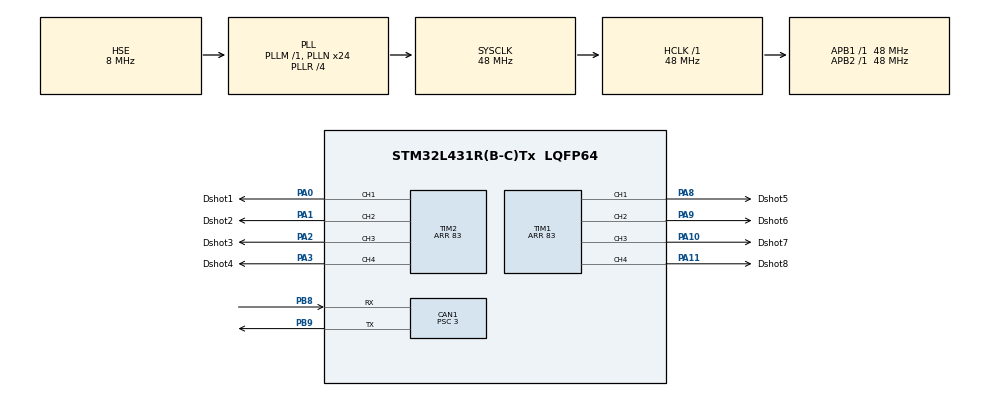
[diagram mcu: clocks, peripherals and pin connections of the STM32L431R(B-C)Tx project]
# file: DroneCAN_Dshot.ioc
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CAN1.ABOM=ENABLE
CAN1.BS1=CAN_BS1_13TQ
CAN1.BS2=CAN_BS2_2TQ
CAN1.CalculateBaudRate=1000000
CAN1.CalculateTimeBit=1000
CAN1.CalculateTimeQuantum=62.5
CAN1.NART=ENABLE
CAN1.Prescaler=3
CAN1.SJW=CAN_SJW_1TQ
Dma.Request0=TIM1_UP
Dma.Request1=TIM2_UP
Dma.TIM1_UP.0.Direction=DMA_MEMORY_TO_PERIPH
Dma.TIM1_UP.0.Instance=DMA1_Channel6
Dma.TIM1_UP.0.MemDataAlignment=DMA_MDATAALIGN_WORD
Dma.TIM1_UP.0.MemInc=DMA_MINC_ENABLE
Dma.TIM1_UP.0.Mode=DMA_NORMAL
Dma.TIM1_UP.0.PeriphDataAlignment=DMA_PDATAALIGN_WORD
Dma.TIM1_UP.0.PeriphInc=DMA_PINC_DISABLE
Dma.TIM1_UP.0.Priority=DMA_PRIORITY_VERY_HIGH
Dma.TIM2_UP.1.Direction=DMA_MEMORY_TO_PERIPH
Dma.TIM2_UP.1.Instance=DMA1_Channel2
Dma.TIM2_UP.1.MemDataAlignment=DMA_MDATAALIGN_WORD
Dma.TIM2_UP.1.MemInc=DMA_MINC_ENABLE
Dma.TIM2_UP.1.Mode=DMA_NORMAL
Dma.TIM2_UP.1.PeriphDataAlignment=DMA_PDATAALIGN_WORD
Dma.TIM2_UP.1.PeriphInc=DMA_PINC_DISABLE
Dma.TIM2_UP.1.Priority=DMA_PRIORITY_VERY_HIGH
IWDG.Prescaler=IWDG_PRESCALER_32
IWDG.Reload=399
Mcu.Family=STM32L4
Mcu.Name=STM32L431R(B-C)Tx
Mcu.Package=LQFP64
NVIC.CAN1_RX0_IRQn=true\:2\:0\:false\:false\:true\:true\:true\:true
NVIC.DMA1_Channel2_IRQn=true\:0\:0\:false\:false\:true\:false\:true\:true
NVIC.DMA1_Channel6_IRQn=true\:0\:0\:false\:false\:true\:false\:true\:true
NVIC.PriorityGroup=NVIC_PRIORITYGROUP_4
NVIC.TIM6_DAC_IRQn=true\:0\:0\:false\:false\:true\:true\:true\:true
NVIC.TIM7_IRQn=true\:0\:0\:false\:false\:true\:true\:true\:true
PA0.GPIO_Label=Dshot1
PA0.GPIO_Speed=GPIO_SPEED_FREQ_VERY_HIGH
PA0.Signal=S_TIM2_CH1
PA1.GPIO_Label=Dshot2
PA1.GPIO_Speed=GPIO_SPEED_FREQ_VERY_HIGH
PA1.Signal=S_TIM2_CH2
PA10.GPIO_Label=Dshot7
PA10.GPIO_Speed=GPIO_SPEED_FREQ_VERY_HIGH
PA10.Signal=S_TIM1_CH3
PA11.GPIO_Label=Dshot8
PA11.GPIO_Speed=GPIO_SPEED_FREQ_VERY_HIGH
PA11.Signal=S_TIM1_CH4
PA13\ (JTMS-SWDIO).Mode=Serial_Wire
PA13\ (JTMS-SWDIO).Signal=SYS_JTMS-SWDIO
PA14\ (JTCK-SWCLK).Mode=Serial_Wire
PA14\ (JTCK-SWCLK).Signal=SYS_JTCK-SWCLK
PA2.GPIO_Label=Dshot3
PA2.GPIO_Speed=GPIO_SPEED_FREQ_VERY_HIGH
PA2.Signal=S_TIM2_CH3
PA3.GPIO_Label=Dshot4
PA3.GPIO_Speed=GPIO_SPEED_FREQ_VERY_HIGH
PA3.Signal=S_TIM2_CH4
PA8.GPIO_Label=Dshot5
PA8.GPIO_Speed=GPIO_SPEED_FREQ_VERY_HIGH
PA8.Signal=S_TIM1_CH1
PA9.GPIO_Label=Dshot6
PA9.GPIO_Speed=GPIO_SPEED_FREQ_VERY_HIGH
PA9.Signal=S_TIM1_CH2
PB8.Mode=CAN_Activate
PB8.Signal=CAN1_RX
PB9.Mode=CAN_Activate
PB9.Signal=CAN1_TX
PH0-OSC_IN\ (PH0).Mode=HSE-External-Oscillator
PH0-OSC_IN\ (PH0).Signal=RCC_OSC_IN
PH1-OSC_OUT\ (PH1).Mode=HSE-External-Oscillator
PH1-OSC_OUT\ (PH1).Signal=RCC_OSC_OUT
ProjectManager.HeapSize=0x200
ProjectManager.StackSize=0x400
ProjectManager.TargetToolchain=CMake
RCC.ADCFreq_Value=32000000
RCC.AHBFreq_Value=48000000
RCC.APB1Freq_Value=48000000
RCC.APB1TimFreq_Value=48000000
RCC.APB2Freq_Value=48000000
RCC.APB2TimFreq_Value=48000000
RCC.CortexFreq_Value=48000000
RCC.HCLKFreq_Value=48000000
RCC.HSE_VALUE=8000000
RCC.HSI48_VALUE=48000000
RCC.HSI_VALUE=16000000
RCC.LSE_VALUE=32768
RCC.MSI_VALUE=4000000
RCC.PLLN=24
RCC.PLLR=RCC_PLLR_DIV4
RCC.PLLSourceVirtual=RCC_PLLSOURCE_HSE
RCC.SYSCLKFreq_VALUE=48000000
RCC.SYSCLKSource=RCC_SYSCLKSOURCE_PLLCLK
RCC.VCOOutputFreq_Value=192000000
SH.S_TIM1_CH1.0=TIM1_CH1,PWM Generation1 CH1
SH.S_TIM1_CH2.0=TIM1_CH2,PWM Generation2 CH2
SH.S_TIM1_CH3.0=TIM1_CH3,PWM Generation3 CH3
SH.S_TIM1_CH4.0=TIM1_CH4,PWM Generation4 CH4
SH.S_TIM2_CH1.0=TIM2_CH1,PWM Generation1 CH1
SH.S_TIM2_CH2.0=TIM2_CH2,PWM Generation2 CH2
SH.S_TIM2_CH3.0=TIM2_CH3,PWM Generation3 CH3
SH.S_TIM2_CH4.0=TIM2_CH4,PWM Generation4 CH4
TIM1.Channel-PWM\ Generation1\ CH1=TIM_CHANNEL_1
TIM1.Channel-PWM\ Generation2\ CH2=TIM_CHANNEL_2
TIM1.Channel-PWM\ Generation3\ CH3=TIM_CHANNEL_3
TIM1.Channel-PWM\ Generation4\ CH4=TIM_CHANNEL_4
TIM1.Period=83
TIM2.Channel-PWM\ Generation1\ CH1=TIM_CHANNEL_1
TIM2.Channel-PWM\ Generation2\ CH2=TIM_CHANNEL_2
TIM2.Channel-PWM\ Generation3\ CH3=TIM_CHANNEL_3
TIM2.Channel-PWM\ Generation4\ CH4=TIM_CHANNEL_4
TIM2.Period=83
TIM6.AutoReloadPreload=TIM_AUTORELOAD_PRELOAD_DISABLE
TIM6.Period=51
TIM6.Prescaler=47
TIM7.AutoReloadPreload=TIM_AUTORELOAD_PRELOAD_DISABLE
TIM7.Period=1499
TIM7.Prescaler=47
TIM7.TIM_MasterOutputTrigger=TIM_TRGO_ENABLE
VP_IWDG_VS_IWDG.Mode=IWDG_Activate
VP_TIM1_VS_ClockSourceINT.Mode=Internal
VP_TIM6_VS_ClockSourceINT.Mode=Enable_Timer
VP_TIM7_VS_ClockSourceINT.Mode=Enable_Timer
board=custom

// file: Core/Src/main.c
/* USER CODE BEGIN Header */
/**
  ******************************************************************************
  * @file           : main.c
  * @brief          : Main program body
  ******************************************************************************
  * @attention
  *
  * <h2><center>&copy; Copyright (c) 2026 STMicroelectronics.
  * All rights reserved.</center></h2>
  *
  * This software component is licensed by ST under BSD 3-Clause license,
  * the "License"; You may not use this file except in compliance with the
  * License. You may obtain a copy of the License at:
  *                        opensource.org/licenses/BSD-3-Clause
  *
  ******************************************************************************
  */
/* USER CODE END Header */
#include "main.h"
#include "can.h"
#include "dma.h"
#include "iwdg.h"
#include "tim.h"
#include "gpio.h"

/* USER CODE BEGIN Includes */
#include "dronecan_app.h"
/* USER CODE END Includes */

void SystemClock_Config(void);

int main(void)
{

  /* MCU Configuration--------------------------------------------------------*/

  /* Reset of all peripherals, Initializes the Flash interface and the Systick. */
  HAL_Init();

  /* USER CODE BEGIN Init */

  #ifdef DEBUG
  __HAL_DBGMCU_FREEZE_IWDG();
  #endif

  /* USER CODE END Init */

  /* Configure the system clock */
  SystemClock_Config();

  /* Initialize all configured peripherals */
  MX_GPIO_Init();
  MX_DMA_Init();
  MX_CAN1_Init();
  MX_TIM1_Init();
  MX_TIM2_Init();
  MX_TIM6_Init();
  MX_TIM7_Init();
  MX_IWDG_Init();
  /* USER CODE BEGIN 2 */
  if (DroneCAN_App_Init() != HAL_OK)
  {
    Error_Handler();
  }

  /* USER CODE END 2 */

  /* Infinite loop */
  while (1)
  {

    /* USER CODE BEGIN 3 */
    DroneCAN_App_Poll();

    //添加400ms的喂狗操作，防止看门狗复位
    HAL_IWDG_Refresh(&hiwdg);
  }
  /* USER CODE END 3 */
}

void SystemClock_Config(void)
{
  RCC_OscInitTypeDef RCC_OscInitStruct = {0};
  RCC_ClkInitTypeDef RCC_ClkInitStruct = {0};

  /** Initializes the RCC Oscillators according to the specified parameters
  * in the RCC_OscInitTypeDef structure.
  */
  RCC_OscInitStruct.OscillatorType = RCC_OSCILLATORTYPE_LSI|RCC_OSCILLATORTYPE_HSE;
  RCC_OscInitStruct.HSEState = RCC_HSE_ON;
  RCC_OscInitStruct.LSIState = RCC_LSI_ON;
  RCC_OscInitStruct.PLL.PLLState = RCC_PLL_ON;
  RCC_OscInitStruct.PLL.PLLSource = RCC_PLLSOURCE_HSE;
  RCC_OscInitStruct.PLL.PLLM = 1;
  RCC_OscInitStruct.PLL.PLLN = 24;
  RCC_OscInitStruct.PLL.PLLP = RCC_PLLP_DIV7;
  RCC_OscInitStruct.PLL.PLLQ = RCC_PLLQ_DIV2;
  RCC_OscInitStruct.PLL.PLLR = RCC_PLLR_DIV4;
  if (HAL_RCC_OscConfig(&RCC_OscInitStruct) != HAL_OK)
  {
    Error_Handler();
  }
  /** Initializes the CPU, AHB and APB buses clocks
  */
  RCC_ClkInitStruct.ClockType = RCC_CLOCKTYPE_HCLK|RCC_CLOCKTYPE_SYSCLK
                              |RCC_CLOCKTYPE_PCLK1|RCC_CLOCKTYPE_PCLK2;
  RCC_ClkInitStruct.SYSCLKSource = RCC_SYSCLKSOURCE_PLLCLK;
  RCC_ClkInitStruct.AHBCLKDivider = RCC_SYSCLK_DIV1;
  RCC_ClkInitStruct.APB1CLKDivider = RCC_HCLK_DIV1;
  RCC_ClkInitStruct.APB2CLKDivider = RCC_HCLK_DIV1;

  if (HAL_RCC_ClockConfig(&RCC_ClkInitStruct, FLASH_LATENCY_2) != HAL_OK)
  {
    Error_Handler();
  }
  /** Configure the main internal regulator output voltage
  */
  if (HAL_PWREx_ControlVoltageScaling(PWR_REGULATOR_VOLTAGE_SCALE1) != HAL_OK)
  {
    Error_Handler();
  }
}

void Error_Handler(void)
{
  __disable_irq();
  while (1)
  {
  }
}

/************************ (C) COPYRIGHT STMicroelectronics *****END OF FILE****/
